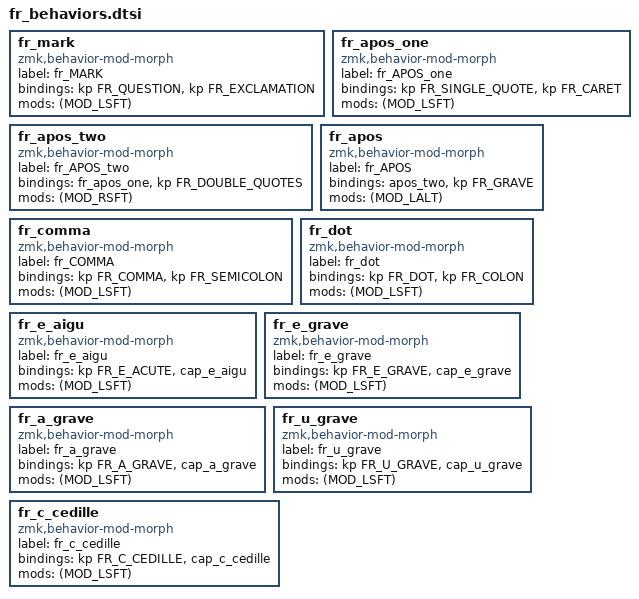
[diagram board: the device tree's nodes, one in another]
// key lshift rshift alt
//  ?     !          
fr_mark: fr_mark {
    compatible = "zmk,behavior-mod-morph";
    label = "fr_MARK";
    #binding-cells = <0>;
    bindings = <&kp FR_QUESTION>, <&kp FR_EXCLAMATION>;
    mods = <(MOD_LSFT)>;
};

// key lshift rshift alt
//  '     ^      "    `
fr_apos_one: fr_apos_one {
    compatible = "zmk,behavior-mod-morph";
    label = "fr_APOS_one";
    #binding-cells = <0>;
    bindings = <&kp FR_SINGLE_QUOTE>, <&kp FR_CARET>;
    mods = <(MOD_LSFT)>;
};
fr_apos_two: fr_apos_two {
    compatible = "zmk,behavior-mod-morph";
    label = "fr_APOS_two";
    #binding-cells = <0>;
    bindings = <&fr_apos_one>, <&kp FR_DOUBLE_QUOTES>;
    mods = <(MOD_RSFT)>;
};
fr_apos: fr_apos {
    compatible = "zmk,behavior-mod-morph";
    label = "fr_APOS";
    #binding-cells = <0>;
    bindings = <&apos_two>, <&kp FR_GRAVE>;
    mods = <(MOD_LALT)>;
};

// key lshift rshift alt
//  ,     ;          
fr_comma: fr_comma {
    compatible = "zmk,behavior-mod-morph";
    label = "fr_COMMA";
    #binding-cells = <0>;
    bindings = <&kp FR_COMMA>, <&kp FR_SEMICOLON>;
    mods = <(MOD_LSFT)>;
};

// key lshift rshift alt
//  .     :          
fr_dot: fr_dot {
    compatible = "zmk,behavior-mod-morph";
    label = "fr_dot";
    #binding-cells = <0>;
    bindings = <&kp FR_DOT>, <&kp FR_COLON>;
    mods = <(MOD_LSFT)>;
};

fr_e_aigu: fr_e_aigu {
    compatible = "zmk,behavior-mod-morph";
    label = "fr_e_aigu";
    #binding-cells = <0>;
    bindings = <&kp FR_E_ACUTE>, <&cap_e_aigu>;
    mods = <(MOD_LSFT)>;
};

fr_e_grave: fr_e_grave {
    compatible = "zmk,behavior-mod-morph";
    label = "fr_e_grave";
    #binding-cells = <0>;
    bindings = <&kp FR_E_GRAVE>, <&cap_e_grave>;
    mods = <(MOD_LSFT)>;
    
};

fr_a_grave: fr_a_grave {
    compatible = "zmk,behavior-mod-morph";
    label = "fr_a_grave";
    #binding-cells = <0>;
    bindings = <&kp FR_A_GRAVE>, <&cap_a_grave>;
    mods = <(MOD_LSFT)>;
    
};

fr_u_grave: fr_u_grave {
    compatible = "zmk,behavior-mod-morph";
    label = "fr_u_grave";
    #binding-cells = <0>;
    bindings = <&kp FR_U_GRAVE>, <&cap_u_grave>;
    mods = <(MOD_LSFT)>;
    
};

fr_c_cedille: fr_c_cedille {
    compatible = "zmk,behavior-mod-morph";
    label = "fr_c_cedille";
    #binding-cells = <0>;
    bindings = <&kp FR_C_CEDILLE>, <&cap_c_cedille>;
    mods = <(MOD_LSFT)>;
    
};
